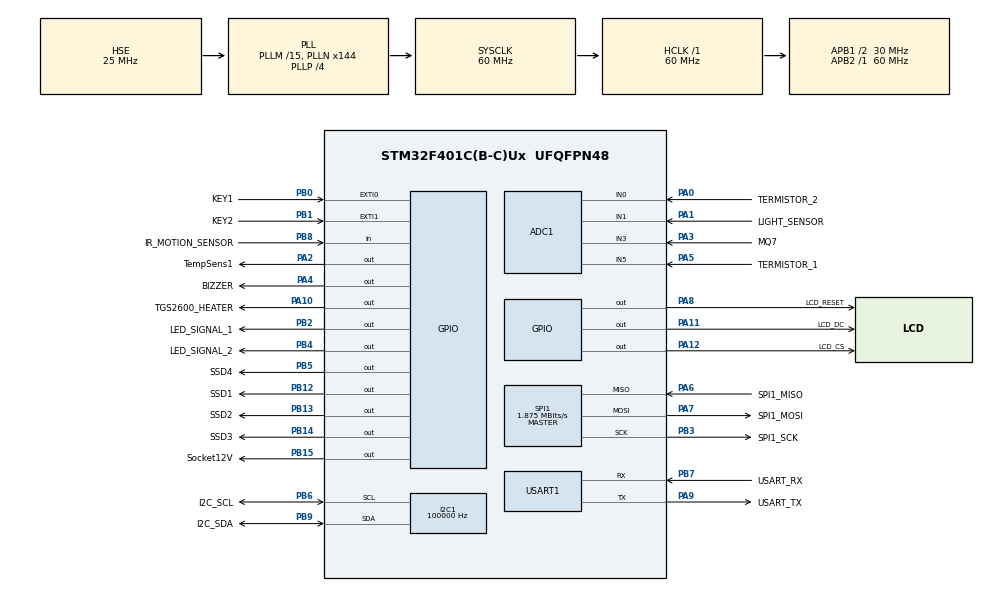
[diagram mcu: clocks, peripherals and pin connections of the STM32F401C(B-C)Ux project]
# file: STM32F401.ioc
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ADC1.Channel-10\#ChannelInjectedConversion=ADC_CHANNEL_5
ADC1.Channel-11\#ChannelInjectedConversion=ADC_CHANNEL_0
ADC1.Channel-12\#ChannelInjectedConversion=ADC_CHANNEL_1
ADC1.Channel-2\#ChannelRegularConversion=ADC_CHANNEL_3
ADC1.Channel-8\#ChannelInjectedConversion=ADC_CHANNEL_3
ADC1.ContinuousConvMode=DISABLE
ADC1.DMAContinuousRequests=DISABLE
ADC1.EOCSelection=ADC_EOC_SEQ_CONV
ADC1.InjNumberOfConversion=4
ADC1.InjectedConvMode=None
ADC1.InjectedOffset-10\#ChannelInjectedConversion=0
ADC1.InjectedOffset-11\#ChannelInjectedConversion=0
ADC1.InjectedOffset-12\#ChannelInjectedConversion=0
ADC1.InjectedOffset-8\#ChannelInjectedConversion=0
ADC1.InjectedRank-10\#ChannelInjectedConversion=2
ADC1.InjectedRank-11\#ChannelInjectedConversion=3
ADC1.InjectedRank-12\#ChannelInjectedConversion=4
ADC1.InjectedRank-8\#ChannelInjectedConversion=1
ADC1.NbrOfConversion=1
ADC1.NbrOfConversionFlag=1
ADC1.Rank-2\#ChannelRegularConversion=1
ADC1.SamplingTime-10\#ChannelInjectedConversion=ADC_SAMPLETIME_28CYCLES
ADC1.SamplingTime-11\#ChannelInjectedConversion=ADC_SAMPLETIME_28CYCLES
ADC1.SamplingTime-12\#ChannelInjectedConversion=ADC_SAMPLETIME_28CYCLES
ADC1.SamplingTime-2\#ChannelRegularConversion=ADC_SAMPLETIME_3CYCLES
ADC1.SamplingTime-8\#ChannelInjectedConversion=ADC_SAMPLETIME_28CYCLES
ADC1.master=1
Dma.Request0=USART1_RX
Dma.Request1=USART1_TX
Dma.USART1_RX.0.Direction=DMA_PERIPH_TO_MEMORY
Dma.USART1_RX.0.FIFOMode=DMA_FIFOMODE_DISABLE
Dma.USART1_RX.0.Instance=DMA2_Stream2
Dma.USART1_RX.0.MemDataAlignment=DMA_MDATAALIGN_BYTE
Dma.USART1_RX.0.MemInc=DMA_MINC_ENABLE
Dma.USART1_RX.0.Mode=DMA_NORMAL
Dma.USART1_RX.0.PeriphDataAlignment=DMA_PDATAALIGN_BYTE
Dma.USART1_RX.0.PeriphInc=DMA_PINC_DISABLE
Dma.USART1_RX.0.Priority=DMA_PRIORITY_LOW
Dma.USART1_TX.1.Direction=DMA_MEMORY_TO_PERIPH
Dma.USART1_TX.1.FIFOMode=DMA_FIFOMODE_DISABLE
Dma.USART1_TX.1.Instance=DMA2_Stream7
Dma.USART1_TX.1.MemDataAlignment=DMA_MDATAALIGN_BYTE
Dma.USART1_TX.1.MemInc=DMA_MINC_ENABLE
Dma.USART1_TX.1.Mode=DMA_CIRCULAR
Dma.USART1_TX.1.PeriphDataAlignment=DMA_PDATAALIGN_BYTE
Dma.USART1_TX.1.PeriphInc=DMA_PINC_DISABLE
Dma.USART1_TX.1.Priority=DMA_PRIORITY_LOW
FREERTOS.INCLUDE_vTaskDelayUntil=1
FREERTOS.Tasks01=defaultTask,0,128,StartDefaultTask,Default,NULL,Dynamic,NULL,NULL
FREERTOS.configENABLE_FPU=1
FREERTOS.configGENERATE_RUN_TIME_STATS=1
FREERTOS.configQUEUE_REGISTRY_SIZE=20
FREERTOS.configTIMER_TASK_PRIORITY=6
FREERTOS.configUSE_CO_ROUTINES=1
FREERTOS.configUSE_RECURSIVE_MUTEXES=1
FREERTOS.configUSE_TICK_HOOK=1
FREERTOS.configUSE_TIMERS=1
I2C1.ClockSpeed=100000
Mcu.Family=STM32F4
Mcu.Name=STM32F401C(B-C)Ux
Mcu.Package=UFQFPN48
NVIC.DMA2_Stream2_IRQn=true\:0\:0\:false\:false\:true\:true\:false\:true
NVIC.DMA2_Stream7_IRQn=true\:0\:0\:false\:false\:true\:true\:false\:true
NVIC.EXTI0_IRQn=true\:0\:0\:false\:false\:true\:false\:true\:true
NVIC.EXTI1_IRQn=true\:0\:0\:false\:false\:true\:false\:true\:true
NVIC.PriorityGroup=NVIC_PRIORITYGROUP_4
NVIC.TIM2_IRQn=true\:0\:0\:false\:false\:true\:true\:true\:true
NVIC.TIM3_IRQn=true\:0\:0\:false\:false\:true\:false\:false\:true
NVIC.TimeBase=TIM3_IRQn
NVIC.TimeBaseIP=TIM3
NVIC.USART1_IRQn=true\:0\:0\:false\:false\:true\:true\:true\:true
PA0-WKUP.GPIO_Label=TERMISTOR_2
PA0-WKUP.Signal=ADCx_IN0
PA1.GPIO_Label=LIGHT_SENSOR
PA1.Signal=ADCx_IN1
PA10.GPIO_Label=TGS2600_HEATER
PA10.PinState=GPIO_PIN_SET
PA10.Signal=GPIO_Output
PA11.GPIO_Label=LCD_DC
PA11.PinState=GPIO_PIN_SET
PA11.Signal=GPIO_Output
PA12.GPIO_Label=LCD_CS
PA12.PinState=GPIO_PIN_SET
PA12.Signal=GPIO_Output
PA13.Mode=Serial_Wire
PA13.Signal=SYS_JTMS-SWDIO
PA14.Mode=Serial_Wire
PA14.Signal=SYS_JTCK-SWCLK
PA2.GPIO_Label=TempSens1
PA2.PinState=GPIO_PIN_SET
PA2.Signal=GPIO_Output
PA3.GPIO_Label=MQ7
PA3.Signal=ADCx_IN3
PA4.GPIO_Label=BIZZER
PA4.GPIO_ModeDefaultOutputPP=GPIO_MODE_OUTPUT_PP
PA4.GPIO_PuPd=GPIO_NOPULL
PA4.PinState=GPIO_PIN_SET
PA4.Signal=GPIO_Output
PA5.GPIO_Label=TERMISTOR_1
PA5.Signal=ADCx_IN5
PA6.GPIO_Label=SPI1_MISO
PA6.Mode=Full_Duplex_Master
PA6.Signal=SPI1_MISO
PA7.GPIO_Label=SPI1_MOSI
PA7.Mode=Full_Duplex_Master
PA7.Signal=SPI1_MOSI
PA8.GPIO_Label=LCD_RESET
PA8.PinState=GPIO_PIN_SET
PA8.Signal=GPIO_Output
PA9.GPIO_Label=USART_TX
PA9.Mode=Asynchronous
PA9.Signal=USART1_TX
PB0.GPIO_Label=KEY1
PB0.GPIO_ModeDefaultEXTI=GPIO_MODE_IT_RISING_FALLING
PB0.Signal=GPXTI0
PB1.GPIO_Label=KEY2
PB1.GPIO_ModeDefaultEXTI=GPIO_MODE_IT_RISING_FALLING
PB1.Signal=GPXTI1
PB12.GPIO_Label=SSD1
PB12.Signal=GPIO_Output
PB13.GPIO_Label=SSD2
PB13.Signal=GPIO_Output
PB14.GPIO_Label=SSD3
PB14.Signal=GPIO_Output
PB15.GPIO_Label=Socket12V
PB15.Signal=GPIO_Output
PB2.GPIO_Label=LED_SIGNAL_1
PB2.Signal=GPIO_Output
PB3.GPIO_Label=SPI1_SCK
PB3.Mode=Full_Duplex_Master
PB3.Signal=SPI1_SCK
PB4.GPIO_Label=LED_SIGNAL_2
PB4.Signal=GPIO_Output
PB5.GPIO_Label=SSD4
PB5.Signal=GPIO_Output
PB6.GPIO_Label=I2C_SCL
PB6.Mode=I2C
PB6.Signal=I2C1_SCL
PB7.GPIO_Label=USART_RX
PB7.Mode=Asynchronous
PB7.Signal=USART1_RX
PB8.GPIO_Label=IR_MOTION_SENSOR
PB8.Signal=GPIO_Input
PB9.GPIO_Label=I2C_SDA
PB9.Mode=I2C
PB9.Signal=I2C1_SDA
PC14-OSC32_IN.Mode=LSE-External-Oscillator
PC14-OSC32_IN.Signal=RCC_OSC32_IN
PC15-OSC32_OUT.Mode=LSE-External-Oscillator
PC15-OSC32_OUT.Signal=RCC_OSC32_OUT
PH0\ -\ OSC_IN.Mode=HSE-External-Oscillator
PH0\ -\ OSC_IN.Signal=RCC_OSC_IN
PH1\ -\ OSC_OUT.Mode=HSE-External-Oscillator
PH1\ -\ OSC_OUT.Signal=RCC_OSC_OUT
ProjectManager.HeapSize=0x400
ProjectManager.StackSize=0x800
ProjectManager.TargetToolchain=Other Toolchains (GPDSC)
RCC.48MHZClocksFreq_Value=48000000
RCC.AHBFreq_Value=60000000
RCC.APB1CLKDivider=RCC_HCLK_DIV2
RCC.APB1Freq_Value=30000000
RCC.APB1TimFreq_Value=60000000
RCC.APB2Freq_Value=60000000
RCC.APB2TimFreq_Value=60000000
RCC.CortexFreq_Value=60000000
RCC.HCLKFreq_Value=60000000
RCC.HSE_VALUE=25000000
RCC.HSI_VALUE=16000000
RCC.PLLM=15
RCC.PLLN=144
RCC.PLLP=RCC_PLLP_DIV4
RCC.PLLQ=5
RCC.PLLSourceVirtual=RCC_PLLSOURCE_HSE
RCC.RCC_RTC_Clock_Source=RCC_RTCCLKSOURCE_LSE
RCC.RCC_RTC_Clock_SourceVirtual=RCC_RTCCLKSOURCE_LSE
RCC.SYSCLKFreq_VALUE=60000000
RCC.SYSCLKSource=RCC_SYSCLKSOURCE_PLLCLK
RCC.VCOOutputFreq_Value=240000000
RTC.Format=RTC_FORMAT_BIN
SH.ADCx_IN0.0=ADC1_IN0,IN0
SH.ADCx_IN1.0=ADC1_IN1,IN1
SH.ADCx_IN3.0=ADC1_IN3,IN3
SH.ADCx_IN5.0=ADC1_IN5,IN5
SPI1.BaudRatePrescaler=SPI_BAUDRATEPRESCALER_32
SPI1.CalculateBaudRate=1.875 MBits/s
SPI1.Direction=SPI_DIRECTION_2LINES
SPI1.Mode=SPI_MODE_MASTER
SPI1.VirtualType=VM_MASTER
TIM1.Period=0xffff-1
TIM1.Prescaler=60-1
TIM2.Period=10000-1
TIM2.Prescaler=6000-1
USART1.VirtualMode=VM_ASYNC
VP_FREERTOS_VS_CMSIS_V1.Mode=CMSIS_V1
VP_RTC_VS_RTC_Activate.Mode=RTC_Enabled
VP_RTC_VS_RTC_Calendar.Mode=RTC_Calendar
VP_SYS_VS_tim3.Mode=TIM3
VP_TIM1_VS_ClockSourceINT.Mode=Internal
VP_TIM2_VS_ClockSourceINT.Mode=Internal
board=custom

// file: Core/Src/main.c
/* USER CODE BEGIN Header */
/**
  ******************************************************************************
  * @file           : main.c
  * @brief          : Main program body
  ******************************************************************************
  * @attention
  *
  * <h2><center>&copy; Copyright (c) 2021 STMicroelectronics.
  * All rights reserved.</center></h2>
  *
  * This software component is licensed by ST under Ultimate Liberty license
  * SLA0044, the "License"; You may not use this file except in compliance with
  * the License. You may obtain a copy of the License at:
  *                             www.st.com/SLA0044
  *
  ******************************************************************************
  */
/* USER CODE END Header */
#include "main.h"
#include "cmsis_os.h"
#include "adc.h"
#include "dma.h"
#include "i2c.h"
#include "rtc.h"
#include "spi.h"
#include "tim.h"
#include "usart.h"
#include "gpio.h"

void SystemClock_Config(void);
void MX_FREERTOS_Init(void);

int main(void)
{

  /* MCU Configuration--------------------------------------------------------*/

  /* Reset of all peripherals, Initializes the Flash interface and the Systick. */
  HAL_Init();

  /* Configure the system clock */
  SystemClock_Config();

  /* Initialize all configured peripherals */
  MX_GPIO_Init();
  MX_DMA_Init();
  MX_I2C1_Init();
  MX_RTC_Init();
  MX_TIM1_Init();
  MX_TIM2_Init();
  MX_ADC1_Init();
  MX_USART1_UART_Init();
  MX_SPI1_Init();

  /* Call init function for freertos objects (in freertos.c) */
  MX_FREERTOS_Init();
  /* Start scheduler */
  osKernelStart();

  /* We should never get here as control is now taken by the scheduler */
  /* Infinite loop */
  while (1)
  {

  }
}

void SystemClock_Config(void)
{
  RCC_OscInitTypeDef RCC_OscInitStruct = {0};
  RCC_ClkInitTypeDef RCC_ClkInitStruct = {0};
  RCC_PeriphCLKInitTypeDef PeriphClkInitStruct = {0};

  /** Configure the main internal regulator output voltage
  */
  __HAL_RCC_PWR_CLK_ENABLE();
  __HAL_PWR_VOLTAGESCALING_CONFIG(PWR_REGULATOR_VOLTAGE_SCALE2);
  /** Initializes the RCC Oscillators according to the specified parameters
  * in the RCC_OscInitTypeDef structure.
  */
  RCC_OscInitStruct.OscillatorType = RCC_OSCILLATORTYPE_HSE|RCC_OSCILLATORTYPE_LSE;
  RCC_OscInitStruct.HSEState = RCC_HSE_ON;
  RCC_OscInitStruct.LSEState = RCC_LSE_ON;
  RCC_OscInitStruct.PLL.PLLState = RCC_PLL_ON;
  RCC_OscInitStruct.PLL.PLLSource = RCC_PLLSOURCE_HSE;
  RCC_OscInitStruct.PLL.PLLM = 15;
  RCC_OscInitStruct.PLL.PLLN = 144;
  RCC_OscInitStruct.PLL.PLLP = RCC_PLLP_DIV4;
  RCC_OscInitStruct.PLL.PLLQ = 5;
  if (HAL_RCC_OscConfig(&RCC_OscInitStruct) != HAL_OK)
  {
    Error_Handler();
  }
  /** Initializes the CPU, AHB and APB buses clocks
  */
  RCC_ClkInitStruct.ClockType = RCC_CLOCKTYPE_HCLK|RCC_CLOCKTYPE_SYSCLK
                              |RCC_CLOCKTYPE_PCLK1|RCC_CLOCKTYPE_PCLK2;
  RCC_ClkInitStruct.SYSCLKSource = RCC_SYSCLKSOURCE_PLLCLK;
  RCC_ClkInitStruct.AHBCLKDivider = RCC_SYSCLK_DIV1;
  RCC_ClkInitStruct.APB1CLKDivider = RCC_HCLK_DIV2;
  RCC_ClkInitStruct.APB2CLKDivider = RCC_HCLK_DIV1;

  if (HAL_RCC_ClockConfig(&RCC_ClkInitStruct, FLASH_LATENCY_1) != HAL_OK)
  {
    Error_Handler();
  }
  PeriphClkInitStruct.PeriphClockSelection = RCC_PERIPHCLK_RTC;
  PeriphClkInitStruct.RTCClockSelection = RCC_RTCCLKSOURCE_LSE;
  if (HAL_RCCEx_PeriphCLKConfig(&PeriphClkInitStruct) != HAL_OK)
  {
    Error_Handler();
  }
}

void HAL_TIM_PeriodElapsedCallback(TIM_HandleTypeDef *htim)
{
  if (htim->Instance == TIM3) {
    HAL_IncTick();
  }
}

void Error_Handler(void)
{
}

/************************ (C) COPYRIGHT STMicroelectronics *****END OF FILE****/

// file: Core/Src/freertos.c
/* USER CODE BEGIN Header */
/**
  ******************************************************************************
  * File Name          : freertos.c
  * Description        : Code for freertos applications
  ******************************************************************************
  * @attention
  *
  * <h2><center>&copy; Copyright (c) 2021 STMicroelectronics.
  * All rights reserved.</center></h2>
  *
  * This software component is licensed by ST under Ultimate Liberty license
  * SLA0044, the "License"; You may not use this file except in compliance with
  * the License. You may obtain a copy of the License at:
  *                             www.st.com/SLA0044
  *
  ******************************************************************************
  */
/* USER CODE END Header */

#include "FreeRTOS.h"
#include "task.h"
#include "main.h"
#include "cmsis_os.h"

osThreadId defaultTaskHandle;

void StartDefaultTask(void const * argument);

void MX_FREERTOS_Init(void); /* (MISRA C 2004 rule 8.1) */

/* GetIdleTaskMemory prototype (linked to static allocation support) */
void vApplicationGetIdleTaskMemory( StaticTask_t **ppxIdleTaskTCBBuffer, StackType_t **ppxIdleTaskStackBuffer, uint32_t *pulIdleTaskStackSize );

/* GetTimerTaskMemory prototype (linked to static allocation support) */
void vApplicationGetTimerTaskMemory( StaticTask_t **ppxTimerTaskTCBBuffer, StackType_t **ppxTimerTaskStackBuffer, uint32_t *pulTimerTaskStackSize );

/* Hook prototypes */
void configureTimerForRunTimeStats(void);
unsigned long getRunTimeCounterValue(void);
void vApplicationTickHook(void);

/* USER CODE BEGIN 1 */
/* Functions needed when configGENERATE_RUN_TIME_STATS is on */
__weak void configureTimerForRunTimeStats(void)
{

}

__weak unsigned long getRunTimeCounterValue(void)
{
return 0;
}
/* USER CODE END 1 */

/* USER CODE BEGIN 3 */
__weak void vApplicationTickHook( void )
{
   /* This function will be called by each tick interrupt if
   configUSE_TICK_HOOK is set to 1 in FreeRTOSConfig.h. User code can be
   added here, but the tick hook is called from an interrupt context, so
   code must not attempt to block, and only the interrupt safe FreeRTOS API
   functions can be used (those that end in FromISR()). */
}
/* USER CODE END 3 */

/* USER CODE BEGIN GET_IDLE_TASK_MEMORY */
static StaticTask_t xIdleTaskTCBBuffer;
static StackType_t xIdleStack[configMINIMAL_STACK_SIZE];

void vApplicationGetIdleTaskMemory( StaticTask_t **ppxIdleTaskTCBBuffer, StackType_t **ppxIdleTaskStackBuffer, uint32_t *pulIdleTaskStackSize )
{
  *ppxIdleTaskTCBBuffer = &xIdleTaskTCBBuffer;
  *ppxIdleTaskStackBuffer = &xIdleStack[0];
  *pulIdleTaskStackSize = configMINIMAL_STACK_SIZE;
  /* place for user code */
}
/* USER CODE END GET_IDLE_TASK_MEMORY */

/* USER CODE BEGIN GET_TIMER_TASK_MEMORY */
static StaticTask_t xTimerTaskTCBBuffer;
static StackType_t xTimerStack[configTIMER_TASK_STACK_DEPTH];

void vApplicationGetTimerTaskMemory( StaticTask_t **ppxTimerTaskTCBBuffer, StackType_t **ppxTimerTaskStackBuffer, uint32_t *pulTimerTaskStackSize )
{
  *ppxTimerTaskTCBBuffer = &xTimerTaskTCBBuffer;
  *ppxTimerTaskStackBuffer = &xTimerStack[0];
  *pulTimerTaskStackSize = configTIMER_TASK_STACK_DEPTH;
  /* place for user code */
}
/* USER CODE END GET_TIMER_TASK_MEMORY */

void MX_FREERTOS_Init(void) {

  /* Create the thread(s) */
  /* definition and creation of defaultTask */
  osThreadDef(defaultTask, StartDefaultTask, osPriorityNormal, 0, 128);
  defaultTaskHandle = osThreadCreate(osThread(defaultTask), NULL);

}

void StartDefaultTask(void const * argument)
{
  for(;;)
  {
    osDelay(1);
  }
}

/************************ (C) COPYRIGHT STMicroelectronics *****END OF FILE****/
